VERSION ""

NS_ :

BS_:

BU_: XXX

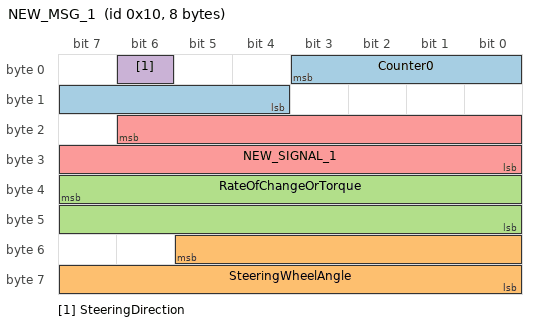
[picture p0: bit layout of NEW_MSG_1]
BO_ 16 NEW_MSG_1: 8 XXX
 SG_ Counter0 : 3|8@0+ (1,0) [0|511] "" XXX
 SG_ SteeringWheelAngle : 53|14@0+ (1,0) [0|65535] "" XXX
 SG_ RateOfChangeOrTorque : 39|16@0+ (1,-32768) [0|65535] "" XXX
 SG_ SteeringDirection : 6|1@0+ (1,0) [0|1] "" XXX
 SG_ NEW_SIGNAL_1 : 22|15@0+ (1,0) [0|65535] "" XXX

CM_ SG_ 16 RateOfChangeOrTorque "Rate of change? Torque?";
CM_ SG_ 16 SteeringDirection "0 = CCW, 1=CW (turning left or right of center)";
